# RCSS_CTRL register map
Vendor: Texas Instruments
Peripheral module from a debugger description file (folder am273).
Registers are 32-bit, read-write, no defined reset value unless marked. A register's access mark holds for its fields unless they carry their own. Offsets are as the file gives them; lines under a group give offsets from that group; [hi:lo] are bit positions; {n}, {i} and the like mark numbered series; 'fields as' and 'values as' point back to an identical list; <NAME> marks a mode.

## RCSS_CTRL
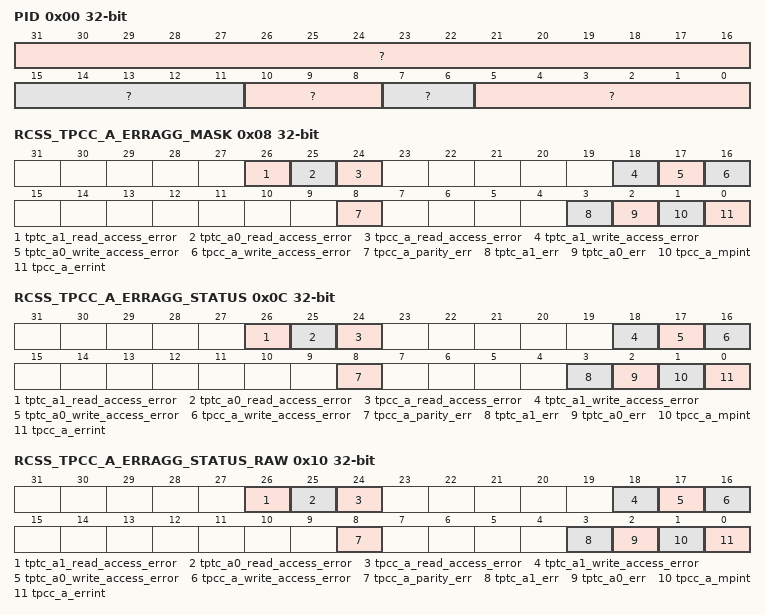
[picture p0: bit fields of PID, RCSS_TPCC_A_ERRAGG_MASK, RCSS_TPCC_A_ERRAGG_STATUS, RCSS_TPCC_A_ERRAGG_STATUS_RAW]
0x00 PID ro
  [31:16] ?, [15:11] ?, [10:8] ?, [7:6] ?, [5:0] ?
0x08 RCSS_TPCC_A_ERRAGG_MASK
  [26] tptc_a1_read_access_error — Mask Error from RCSS_TPTC_A1 to aggregated Error RCSS_TPCC_A_ERRAGG 1 : Error is Masked 0 : Error is Unmasked
  [25] tptc_a0_read_access_error — Mask Error from RCSS_TPTC_A0 to aggregated Error RCSS_TPCC_A_ERRAGG 1 : Error is Masked 0 : Error is Unmasked
  [24] tpcc_a_read_access_error — Mask Error from RCSS_TPCC_A to aggregated Error RCSS_TPCC_A_ERRAGG 1 : Error is Masked 0 : Error is Unmasked
  [18] tptc_a1_write_access_error — Mask Error from RCSS_TPTC_A1 to aggregated Error RCSS_TPCC_A_ERRAGG 1 : Error is Masked 0 : Error is Unmasked
  [17] tptc_a0_write_access_error — Mask Error from RCSS_TPTC_A0 to aggregated Error RCSS_TPCC_A_ERRAGG 1 : Error is Masked 0 : Error is Unmasked
  [16] tpcc_a_write_access_error — Mask Error from RCSS_TPCC_A to aggregated Error RCSS_TPCC_A_ERRAGG 1 : Error is Masked 0 : Error is Unmasked
  [8] tpcc_a_parity_err — Mask Error from RCSS_TPCC_A to aggregated Error RCSS_TPCC_A_ERRAGG 1 : Error is Masked 0 : Error is Unmasked
  [3] tptc_a1_err — Mask Error from RCSS_TPTC_A1 to aggregated Error RCSS_TPCC_A_ERRAGG 1 : Error is Masked 0 : Error is Unmasked
  [2] tptc_a0_err — Mask Error from RCSS_TPTC_A0 to aggregated Error RCSS_TPCC_A_ERRAGG 1 : Error is Masked 0 : Error is Unmasked
  [1] tpcc_a_mpint — Mask Error from RCSS_TPCC_A to aggregated Error RCSS_TPCC_A_ERRAGG 1 : Error is Masked 0 : Error is Unmasked
  [0] tpcc_a_errint — Mask Error from RCSS_TPCC_A to aggregated Error RCSS_TPCC_A_ERRAGG 1 : Error is Masked 0 : Error is Unmasked
0x0C RCSS_TPCC_A_ERRAGG_STATUS
  [26] tptc_a1_read_access_error — Status of Error from RCSS_TPTC_A1. Set only if Interupt is unmasked in RCSS_TPCC_A_ERRAGG_MASK Wrie 0x1 to clear this Error.
  [25] tptc_a0_read_access_error — Status of Error from RCSS_TPTC_A0. Set only if Interupt is unmasked in RCSS_TPCC_A_ERRAGG_MASK Wrie 0x1 to clear this Error.
  [24] tpcc_a_read_access_error — Status of Error from RCSS_TPCC_A. Set only if Interupt is unmasked in RCSS_TPCC_A_ERRAGG_MASK Wrie 0x1 to clear this Error.
  [18] tptc_a1_write_access_error — Status of Error from RCSS_TPTC_A1. Set only if Interupt is unmasked in RCSS_TPCC_A_ERRAGG_MASK Wrie 0x1 to clear this Error.
  [17] tptc_a0_write_access_error — Status of Error from RCSS_TPTC_A0. Set only if Interupt is unmasked in RCSS_TPCC_A_ERRAGG_MASK Wrie 0x1 to clear this Error.
  [16] tpcc_a_write_access_error — Status of Error from RCSS_TPCC_A. Set only if Interupt is unmasked in RCSS_TPCC_A_ERRAGG_MASK Wrie 0x1 to clear this Error.
  [8] tpcc_a_parity_err — Status of Error from RCSS_TPCC_A. Set only if Interupt is unmasked in RCSS_TPCC_A_ERRAGG_MASK Wrie 0x1 to clear this Error.
  [3] tptc_a1_err — Status of Error from RCSS_TPTC_A1. Set only if Interupt is unmasked in RCSS_TPCC_A_ERRAGG_MASK Wrie 0x1 to clear this Error.
  [2] tptc_a0_err — Status of Error from RCSS_TPTC_A0. Set only if Interupt is unmasked in RCSS_TPCC_A_ERRAGG_MASK Wrie 0x1 to clear this Error.
  [1] tpcc_a_mpint — Status of Error from RCSS_TPCC_A. Set only if Interupt is unmasked in RCSS_TPCC_A_ERRAGG_MASK Wrie 0x1 to clear this Error.
  [0] tpcc_a_errint — Status of Error from RCSS_TPCC_A. Set only if Interupt is unmasked in RCSS_TPCC_A_ERRAGG_MASK Wrie 0x1 to clear this Error.
0x10 RCSS_TPCC_A_ERRAGG_STATUS_RAW
  [26] tptc_a1_read_access_error — Raw Status of Error from RCSS_TPTC_A1. Set irrespective if the Interupt is masked or unmasked in RCSS_TPCC_A_ERRAGG_MASK
  [25] tptc_a0_read_access_error — Raw Status of Error from RCSS_TPTC_A0. Set irrespective if the Interupt is masked or unmasked in RCSS_TPCC_A_ERRAGG_MASK
  [24] tpcc_a_read_access_error — Raw Status of Error from RCSS_TPCC_A. Set irrespective if the Interupt is masked or unmasked in RCSS_TPCC_A_ERRAGG_MASK
  [18] tptc_a1_write_access_error — Raw Status of Error from RCSS_TPTC_A1. Set irrespective if the Interupt is masked or unmasked in RCSS_TPCC_A_ERRAGG_MASK
  [17] tptc_a0_write_access_error — Raw Status of Error from RCSS_TPTC_A0. Set irrespective if the Interupt is masked or unmasked in RCSS_TPCC_A_ERRAGG_MASK
  [16] tpcc_a_write_access_error — Raw Status of Error from RCSS_TPCC_A. Set irrespective if the Interupt is masked or unmasked in RCSS_TPCC_A_ERRAGG_MASK
  [8] tpcc_a_parity_err — Raw Status of Error from RCSS_TPCC_A. Set irrespective if the Interupt is masked or unmasked in RCSS_TPCC_A_ERRAGG_MASK
  [3] tptc_a1_err — Raw Status of Error from RCSS_TPTC_A1. Set irrespective if the Interupt is masked or unmasked in RCSS_TPCC_A_ERRAGG_MASK
  [2] tptc_a0_err — Raw Status of Error from RCSS_TPTC_A0. Set irrespective if the Interupt is masked or unmasked in RCSS_TPCC_A_ERRAGG_MASK
  [1] tpcc_a_mpint — Raw Status of Error from RCSS_TPCC_A. Set irrespective if the Interupt is masked or unmasked in RCSS_TPCC_A_ERRAGG_MASK
  [0] tpcc_a_errint — Raw Status of Error from RCSS_TPCC_A. Set irrespective if the Interupt is masked or unmasked in RCSS_TPCC_A_ERRAGG_MASK
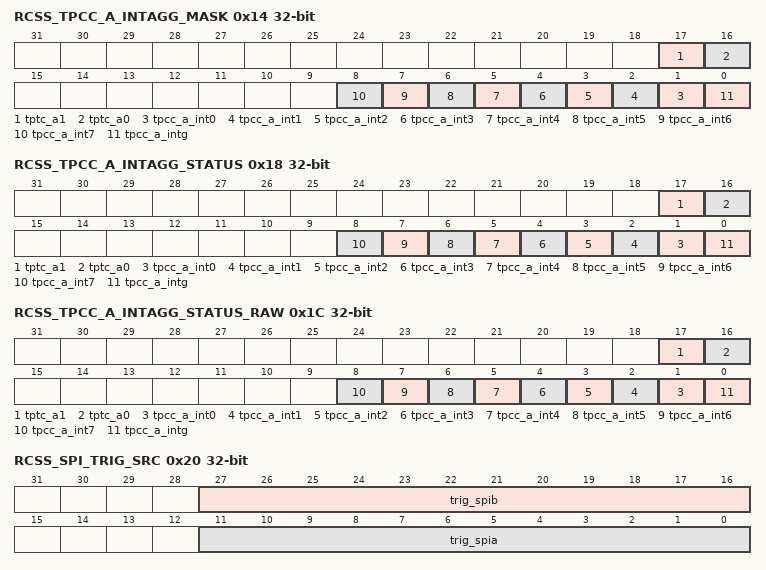
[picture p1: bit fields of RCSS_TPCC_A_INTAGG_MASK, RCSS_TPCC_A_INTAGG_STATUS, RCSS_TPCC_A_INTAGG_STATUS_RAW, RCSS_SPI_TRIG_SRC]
0x14 RCSS_TPCC_A_INTAGG_MASK
  [17] tptc_a1 — Mask Interrupt from TPTC A1 to aggregated Interrupt RCSS_TPCC_A_INTAGG 1 : Interrupt is Masked 0 : Interrupt is Unmasked
  [16] tptc_a0 — Mask Interrupt from TPTC A0 to aggregated Interrupt RCSS_TPCC_A_INTAGG 1 : Interrupt is Masked 0 : Interrupt is Unmasked
  [n+1] tpcc_a_int{n} (n=0..7) — Mask Interrupt from RCSS_TPCC_A to aggregated Interrupt RCSS_TPCC_A_INTAGG 1 : Interrupt is Masked 0 : Interrupt is Unmasked
  [0] tpcc_a_intg — Mask Interrupt from RCSS_TPCC_A to aggregated Interrupt RCSS_TPCC_A_INTAGG 1 : Interrupt is Masked 0 : Interrupt is Unmasked
0x18 RCSS_TPCC_A_INTAGG_STATUS
  [17] tptc_a1 — Status of Interrupt from TPTC A1. Set only if Interupt is unmasked in RCSS_TPCC_A_INTAGG_MASK Wrie 0x1 to clear this interrupt.
  [16] tptc_a0 — Status of Interrupt from TPTC A0. Set only if Interupt is unmasked in RCSS_TPCC_A_INTAGG_MASK Wrie 0x1 to clear this interrupt.
  [n+1] tpcc_a_int{n} (n=0..7) — Status of Interrupt from RCSS_TPCC_A. Set only if Interupt is unmasked in RCSS_TPCC_A_INTAGG_MASK Wrie 0x1 to clear this interrupt.
  [0] tpcc_a_intg — Status of Interrupt from RCSS_TPCC_A. Set only if Interupt is unmasked in RCSS_TPCC_A_INTAGG_MASK Wrie 0x1 to clear this interrupt.
0x1C RCSS_TPCC_A_INTAGG_STATUS_RAW
  [17] tptc_a1 — Raw Status of Interrupt from TPTC A1. Set irrespective if the Interupt is masked or unmasked in RCSS_TPCC_A_INTAGG_MASK
  [16] tptc_a0 — Raw Status of Interrupt from TPTC A0. Set irrespective if the Interupt is masked or unmasked in RCSS_TPCC_A_INTAGG_MASK
  [n+1] tpcc_a_int{n} (n=0..7) — Raw Status of Interrupt from RCSS_TPCC_A. Set irrespective if the Interupt is masked or unmasked in RCSS_TPCC_A_INTAGG_MASK
  [0] tpcc_a_intg — Raw Status of Interrupt from RCSS_TPCC_A. Set irrespective if the Interupt is masked or unmasked in RCSS_TPCC_A_INTAGG_MASK
0x20 RCSS_SPI_TRIG_SRC
  [27:16] trig_spib — Trigger sources for RCSS SPIB
  [11:0] trig_spia — Trigger sources for RCSS SPIA
0x24 RCSS_SPIA_MEMINIT
  [0] mem0_init — Write pulse bit field: Start Memory intialization of memory. Write 0x1 to start memory initilization. Write 0x0 after ensuring Memory intilization is in progress or has completed.
0x28 RCSS_SPIA_MEMINIT_DONE
  [0] mem0_done — Status field. Read value 0x1 indicates previously triggered Memory intialization of memory is complte. Write 0x1 to clear status.
0x2C RCSS_SPIA_MEMINIT_STATUS ro
  [0] mem0_status — Status field. Read value 0x1 indicates previously triggered Memory intialization of memory is in progress.
0x30 RCSS_SPIB_MEMINIT
  fields as RCSS_SPIA_MEMINIT
0x34 RCSS_SPIB_MEMINIT_DONE
  fields as RCSS_SPIA_MEMINIT_DONE
0x38 RCSS_SPIB_MEMINIT_STATUS ro
  fields as RCSS_SPIA_MEMINIT_STATUS
0x3C RCSS_TPCC_MEMINIT_START
  [0] tpcc_a_meminit_start — Write pulse bit field: Start Memory intialization of memory. Write 0x1 to start memory initilization. Write 0x0 after ensuring Memory intilization is in progress or has completed.
0x40 RCSS_TPCC_MEMINIT_DONE
  [0] tpcc_a_meminit_done — Status field. Read value 0x1 indicates previously triggered Memory intialization of memory is complte. Write 0x1 to clear status.
0x44 RCSS_TPCC_MEMINIT_STATUS ro
  [0] tpcc_a_meminit_status — Status field. Read value 0x1 indicates previously triggered Memory intialization of memory is in progress.
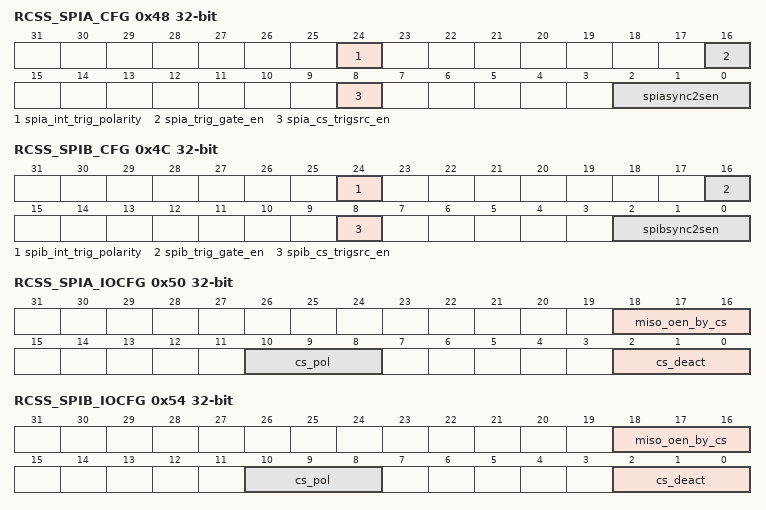
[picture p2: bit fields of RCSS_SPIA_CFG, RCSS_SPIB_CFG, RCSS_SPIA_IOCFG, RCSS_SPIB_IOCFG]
0x48 RCSS_SPIA_CFG
  [24] spia_int_trig_polarity — Trigger source polarity select. Write 0x0 : Polarity 0, Write 0x1 : Polarity 1
  [16] spia_trig_gate_en — Trigger Gate Enable. Write 0x1 : The triggers are un-gated only when chip-select is active
  [8] spia_cs_trigsrc_en — Chip Select Trigger SRC enable, Wrie 0x1 to Use CS as trigger source
  [2:0] spiasync2sen — Donot touch the field. Used as Tie-off for IP-config
0x4C RCSS_SPIB_CFG
  [24] spib_int_trig_polarity — Trigger source polarity select. Write 0x0 : Polarity 0, Write 0x1 : Polarity 1
  [16] spib_trig_gate_en — Trigger Gate Enable. Write 0x1 : The triggers are un-gated only when chip-select is active
  [8] spib_cs_trigsrc_en — Chip Select Trigger SRC enable, Wrie 0x1 to Use CS as trigger source
  [2:0] spibsync2sen — Donot touch the field. Used as Tie-off for IP-config
0x50 RCSS_SPIA_IOCFG
  [18:16] miso_oen_by_cs — SPI MISO Output Enable Control based on Chip select CS. Applicable in slave mode. Write 0x1 : MISO OEN controlled based on CS.When CS is inactive OE_N=1. Write 0x0 : MISO OEN controlled by IP
  [10:8] cs_pol — SPI CS polarity-slave mode. Write 0x1 : Active high. Write 0x0 : Active low
  [2:0] cs_deact — Chip Select Deactivate. Write 0x1 : SPI External chip select is overridden with the value of SPI CS polarity-slave mode
0x54 RCSS_SPIB_IOCFG
  fields as RCSS_SPIA_IOCFG
0x58 RCSS_SPI_HOST_IRQ
  [2:0] host_irq — TI internal reserved for R&D
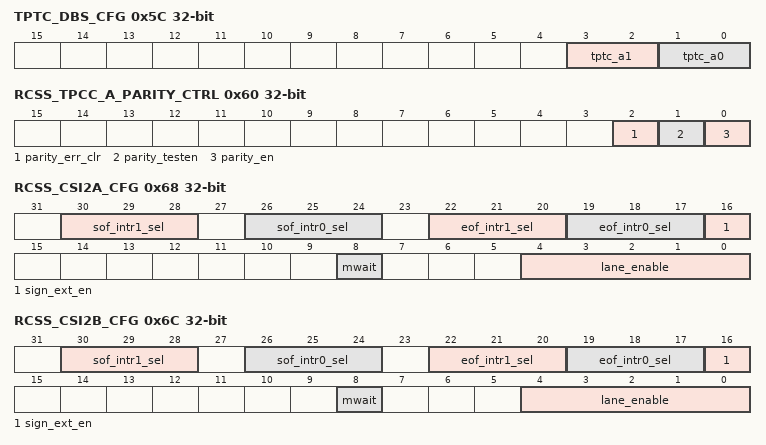
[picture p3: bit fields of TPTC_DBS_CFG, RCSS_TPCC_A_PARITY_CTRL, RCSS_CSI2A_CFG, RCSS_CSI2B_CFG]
0x5C TPTC_DBS_CFG
  [3:2] tptc_a1 — Max Burst size tieoff value for TPTC A1
  [1:0] tptc_a0 — Max Burst size tieoff value for TPTC A0
0x60 RCSS_TPCC_A_PARITY_CTRL
  [2] parity_err_clr — Write pulse bit field: Write 0x1 to clear the Parit Error status for TPCC
  [1] parity_testen — Enable Parity Test for TPCC. Write 0x1 : Parity Test is enabled on PARAM memory
  [0] parity_en — Enable Parity for TPCC. Write 0x1 : Parity is enabled on PARAM memory
0x64 RCSS_TPCC_A_PARITY_STATUS ro
  [15:8] parity_addr — TPCC Error Address at which Parity Error occurred
0x68 RCSS_CSI2A_CFG
  [30:28] sof_intr1_sel — Select the Start of Frame Contx to be sent as RCSS_CSI2A_SOF_INT1 Write 0 : Start of Frame for Context 0 will be propagated on this interrupt line Write 7 : Start of Frame for Context 7 will be propagated on this interrupt line
  [26:24] sof_intr0_sel — Select the Start of Frame Contx to be sent as RCSS_CSI2A_SOF_INT0 Write 0 : Start of Frame for Context 0 will be propagated on this interrupt line Write 7 : Start of Frame for Context 7 will be propagated on this interrupt line
  [22:20] eof_intr1_sel — Select the End of Frame Contx to be sent as RCSS_CSI2A_EOF_INT1 Write 0 : End of Frame for Context 0 will be propagated on this interrupt line Write 7 : End of Frame for Context 7 will be propagated on this interrupt line
  [19:17] eof_intr0_sel — Select the End of Frame Contx to be sent as RCSS_CSI2A_EOF_INT0 Write 0 : End of Frame for Context 0 will be propagated on this interrupt line Write 7 : End of Frame for Context 7 will be propagated on this interrupt line
  [16] sign_ext_en — Sign Extention Enable for CSI2 A
  [8] mwait — Power Idle Protocol related Mwait Port
  [4:0] lane_enable — Lane enable for CSI2 A
0x6C RCSS_CSI2B_CFG
  [30:28] sof_intr1_sel — Select the Start of Frame Contx to be sent as RCSS_CSI2B_SOF_INT1 Write 0 : Start of Frame for Context 0 will be propagated on this interrupt line Write 7 : Start of Frame for Context 7 will be propagated on this interrupt line
  [26:24] sof_intr0_sel — Select the Start of Frame Contx to be sent as RCSS_CSI2B_SOF_INT0 Write 0 : Start of Frame for Context 0 will be propagated on this interrupt line Write 7 : Start of Frame for Context 7 will be propagated on this interrupt line
  [22:20] eof_intr1_sel — Select the End of Frame Contx to be sent as RCSS_CSI2B_EOF_INT1 Write 0 : End of Frame for Context 0 will be propagated on this interrupt line Write 7 : End of Frame for Context 7 will be propagated on this interrupt line
  [19:17] eof_intr0_sel — Select the End of Frame Contx to be sent as RCSS_CSI2B_EOF_INT0 Write 0 : End of Frame for Context 0 will be propagated on this interrupt line Write 7 : End of Frame for Context 7 will be propagated on this interrupt line
  [16] sign_ext_en — Sign Extention Enable for CSI2 B
  [8] mwait — Power Idle Protocol related Mwait Port
  [4:0] lane_enable — Lane enable for CSI2 B
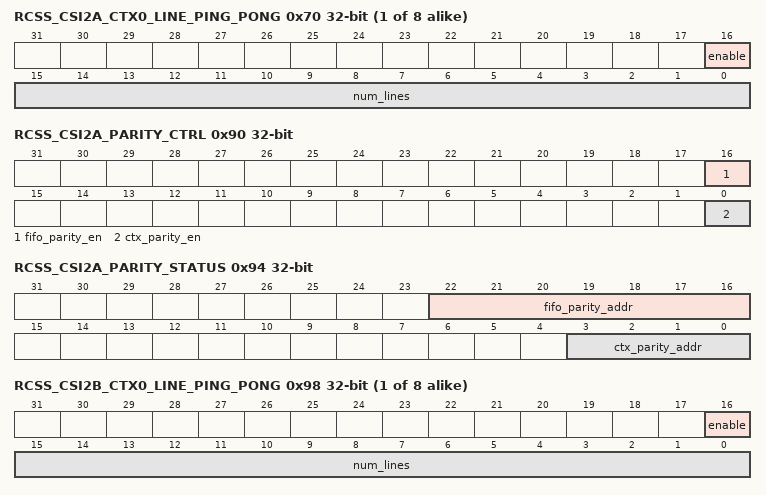
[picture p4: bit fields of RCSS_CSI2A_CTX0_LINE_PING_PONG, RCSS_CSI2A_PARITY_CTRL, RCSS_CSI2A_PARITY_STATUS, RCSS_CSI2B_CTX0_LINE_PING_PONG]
{0x70+4i} RCSS_CSI2A_CTX{i}_LINE_PING_PONG (i=0..7)
  [16] enable — Enable line based ping pong toggle for Context {i} 0 : Diabled 1:Enabled
  [15:0] num_lines — Configure the number of lines for ping pong toggle for Context {i}
0x90 RCSS_CSI2A_PARITY_CTRL
  [16] fifo_parity_en — Enable Parity for CSI2 FIFO Memory. Write 0x1 : Parity is enabled
  [0] ctx_parity_en — Enable Parity for CSI2 CTX Memory. Write 0x1 : Parity is enabled
0x94 RCSS_CSI2A_PARITY_STATUS ro
  [22:16] fifo_parity_addr — CSI2 FIFO Memory Error Address at which Parity Error occurred
  [3:0] ctx_parity_addr — CSI2 CTX Memory Error Address at which Parity Error occurred
{0x98+4i} RCSS_CSI2B_CTX{i}_LINE_PING_PONG (i=0..7)
  fields as RCSS_CSI2A_CTX0_LINE_PING_PONG
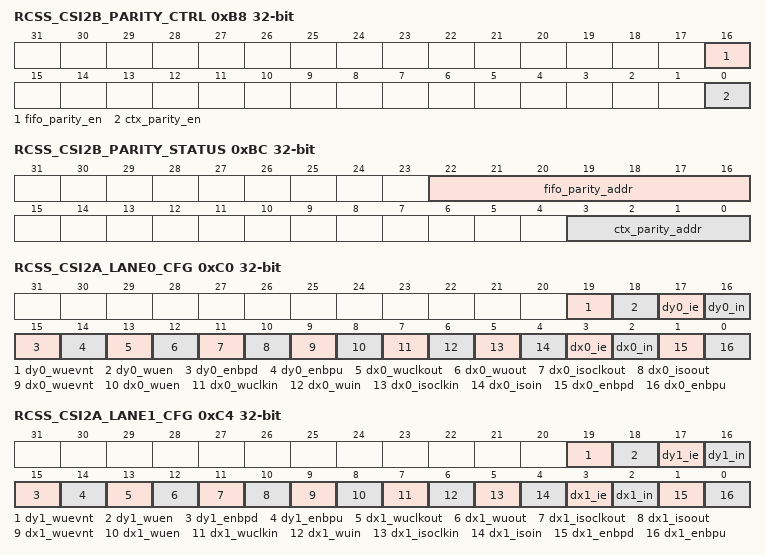
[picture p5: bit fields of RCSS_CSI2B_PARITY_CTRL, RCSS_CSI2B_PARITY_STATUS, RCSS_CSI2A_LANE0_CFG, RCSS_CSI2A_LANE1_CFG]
0xB8 RCSS_CSI2B_PARITY_CTRL
  fields as RCSS_CSI2A_PARITY_CTRL
0xBC RCSS_CSI2B_PARITY_STATUS ro
  fields as RCSS_CSI2A_PARITY_STATUS
0xC0 RCSS_CSI2A_LANE0_CFG access per field
  [19] dy0_wuevnt ro — Pad DY Wakeup Event
  [18] dy0_wuen rw — Pad DY Wakeup Enable
  [17] dy0_ie rw — Pad DY Input Buffer Enable
  [16] dy0_in ro — Pad DY Input
  [15] dy0_enbpd rw — Pad DY Enable Pull Down
  [14] dy0_enbpu rw — Pad DY Enable Pull Up
  [13] dx0_wuclkout ro — Pad DX Wakeup Clkout
  [12] dx0_wuout ro — Pad DX Wakeup Output
  [11] dx0_isoclkout ro — Pad DX Isosaltion Clkout
  [10] dx0_isoout ro — Pad DX Isosaltion Output
  [9] dx0_wuevnt ro — Pad DX Wakeup Event
  [8] dx0_wuen rw — Pad DX Wakeup Enable
  [7] dx0_wuclkin rw — Pad DX Wakeup Clkin
  [6] dx0_wuin rw — Pad DX Wakeup Input
  [5] dx0_isoclkin rw — Pad DX Isolation Clkin
  [4] dx0_isoin rw — Pad DX Isosaltion Input
  [3] dx0_ie rw — Pad DX Input Buffer Enable
  [2] dx0_in ro — Pad DX Input
  [1] dx0_enbpd rw — Pad DX Enable Pull Down
  [0] dx0_enbpu rw — Pad DX Enable Pull Up
0xC4 RCSS_CSI2A_LANE1_CFG access per field
  [19] dy1_wuevnt ro — Pad DY Wakeup Event
  [18] dy1_wuen rw — Pad DY Wakeup Enable
  [17] dy1_ie rw — Pad DY Input Buffer Enable
  [16] dy1_in ro — Pad DY Input
  [15] dy1_enbpd rw — Pad DY Enable Pull Down
  [14] dy1_enbpu rw — Pad DY Enable Pull Up
  [13] dx1_wuclkout ro — Pad DX Wakeup Clkout
  [12] dx1_wuout ro — Pad DX Wakeup Output
  [11] dx1_isoclkout ro — Pad DX Isosaltion Clkout
  [10] dx1_isoout ro — Pad DX Isosaltion Output
  [9] dx1_wuevnt ro — Pad DX Wakeup Event
  [8] dx1_wuen rw — Pad DX Wakeup Enable
  [7] dx1_wuclkin rw — Pad DX Wakeup Clkin
  [6] dx1_wuin rw — Pad DX Wakeup Input
  [5] dx1_isoclkin rw — Pad DX Isolation Clkin
  [4] dx1_isoin rw — Pad DX Isosaltion Input
  [3] dx1_ie rw — Pad DX Input Buffer Enable
  [2] dx1_in ro — Pad DX Input
  [1] dx1_enbpd rw — Pad DX Enable Pull Down
  [0] dx1_enbpu rw — Pad DX Enable Pull Up
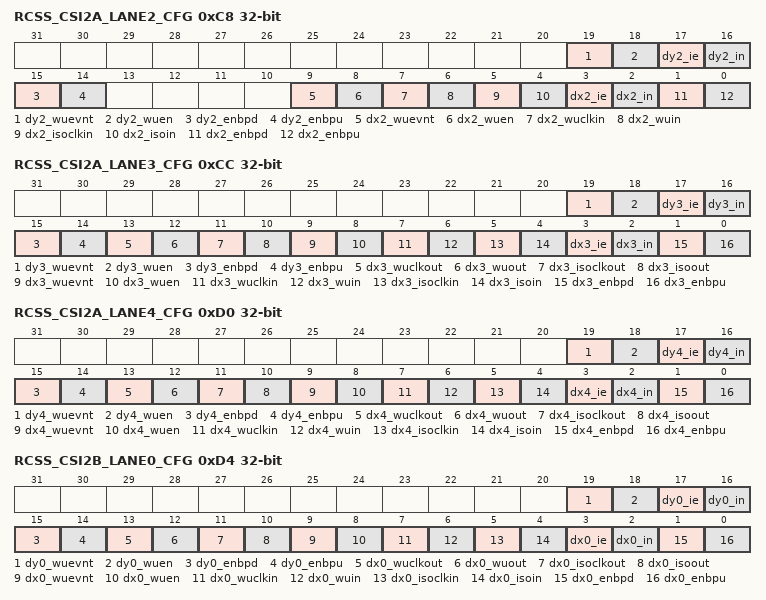
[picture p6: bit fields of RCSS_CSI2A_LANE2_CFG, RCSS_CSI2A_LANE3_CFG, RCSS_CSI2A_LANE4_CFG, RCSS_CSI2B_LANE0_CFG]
0xC8 RCSS_CSI2A_LANE2_CFG access per field
  [19] dy2_wuevnt ro — Pad DY Wakeup Event
  [18] dy2_wuen rw — Pad DY Wakeup Enable
  [17] dy2_ie rw — Pad DY Input Buffer Enable
  [16] dy2_in ro — Pad DY Input
  [15] dy2_enbpd rw — Pad DY Enable Pull Down
  [14] dy2_enbpu rw — Pad DY Enable Pull Up
  [9] dx2_wuevnt ro — Pad DX Wakeup Event
  [8] dx2_wuen rw — Pad DX Wakeup Enable
  [7] dx2_wuclkin rw — Pad DX Wakeup Clkin
  [6] dx2_wuin rw — Pad DX Wakeup Input
  [5] dx2_isoclkin rw — Pad DX Isolation Clkin
  [4] dx2_isoin rw — Pad DX Isosaltion Input
  [3] dx2_ie rw — Pad DX Input Buffer Enable
  [2] dx2_in ro — Pad DX Input
  [1] dx2_enbpd rw — Pad DX Enable Pull Down
  [0] dx2_enbpu rw — Pad DX Enable Pull Up
0xCC RCSS_CSI2A_LANE3_CFG access per field
  [19] dy3_wuevnt ro — Pad DY Wakeup Event
  [18] dy3_wuen rw — Pad DY Wakeup Enable
  [17] dy3_ie rw — Pad DY Input Buffer Enable
  [16] dy3_in ro — Pad DY Input
  [15] dy3_enbpd rw — Pad DY Enable Pull Down
  [14] dy3_enbpu rw — Pad DY Enable Pull Up
  [13] dx3_wuclkout ro — Pad DX Wakeup Clkout
  [12] dx3_wuout ro — Pad DX Wakeup Output
  [11] dx3_isoclkout ro — Pad DX Isosaltion Clkout
  [10] dx3_isoout ro — Pad DX Isosaltion Output
  [9] dx3_wuevnt ro — Pad DX Wakeup Event
  [8] dx3_wuen rw — Pad DX Wakeup Enable
  [7] dx3_wuclkin rw — Pad DX Wakeup Clkin
  [6] dx3_wuin rw — Pad DX Wakeup Input
  [5] dx3_isoclkin rw — Pad DX Isolation Clkin
  [4] dx3_isoin rw — Pad DX Isosaltion Input
  [3] dx3_ie rw — Pad DX Input Buffer Enable
  [2] dx3_in ro — Pad DX Input
  [1] dx3_enbpd rw — Pad DX Enable Pull Down
  [0] dx3_enbpu rw — Pad DX Enable Pull Up
0xD0 RCSS_CSI2A_LANE4_CFG access per field
  [19] dy4_wuevnt ro — Pad DY Wakeup Event
  [18] dy4_wuen rw — Pad DY Wakeup Enable
  [17] dy4_ie rw — Pad DY Input Buffer Enable
  [16] dy4_in ro — Pad DY Input
  [15] dy4_enbpd rw — Pad DY Enable Pull Down
  [14] dy4_enbpu rw — Pad DY Enable Pull Up
  [13] dx4_wuclkout ro — Pad DX Wakeup Clkout
  [12] dx4_wuout ro — Pad DX Wakeup Output
  [11] dx4_isoclkout ro — Pad DX Isosaltion Clkout
  [10] dx4_isoout ro — Pad DX Isosaltion Output
  [9] dx4_wuevnt ro — Pad DX Wakeup Event
  [8] dx4_wuen rw — Pad DX Wakeup Enable
  [7] dx4_wuclkin rw — Pad DX Wakeup Clkin
  [6] dx4_wuin rw — Pad DX Wakeup Input
  [5] dx4_isoclkin rw — Pad DX Isolation Clkin
  [4] dx4_isoin rw — Pad DX Isosaltion Input
  [3] dx4_ie rw — Pad DX Input Buffer Enable
  [2] dx4_in ro — Pad DX Input
  [1] dx4_enbpd rw — Pad DX Enable Pull Down
  [0] dx4_enbpu rw — Pad DX Enable Pull Up
0xD4 RCSS_CSI2B_LANE0_CFG access per field
  fields as RCSS_CSI2A_LANE0_CFG
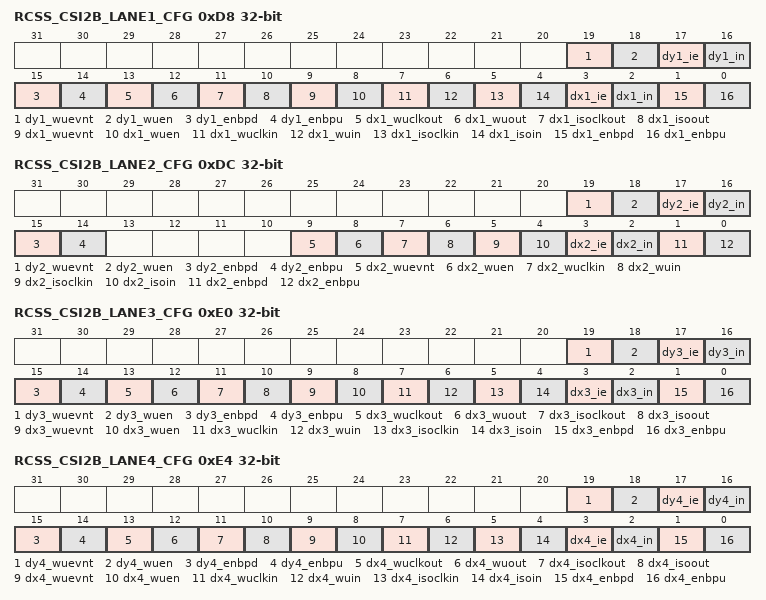
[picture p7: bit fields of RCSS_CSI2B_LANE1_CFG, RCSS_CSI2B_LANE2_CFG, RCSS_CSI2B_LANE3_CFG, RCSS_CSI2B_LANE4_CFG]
0xD8 RCSS_CSI2B_LANE1_CFG access per field
  fields as RCSS_CSI2A_LANE1_CFG
0xDC RCSS_CSI2B_LANE2_CFG access per field
  fields as RCSS_CSI2A_LANE2_CFG
0xE0 RCSS_CSI2B_LANE3_CFG access per field
  fields as RCSS_CSI2A_LANE3_CFG
0xE4 RCSS_CSI2B_LANE4_CFG access per field
  fields as RCSS_CSI2A_LANE4_CFG
0xE8 RCSS_CSI2A_FIFO_MEMINIT
  [0] start — Write pulse bit field: Start Memory intialization of memory. Write 0x1 to start memory initilization. Write 0x0 after ensuring Memory intilization is in progress or has completed.
0xEC RCSS_CSI2A_FIFO_MEMINIT_DONE
  [0] done — Status field. Read value 0x1 indicates previously triggered Memory intialization of memory is complte. Write 0x1 to clear status.
0xF0 RCSS_CSI2A_FIFO_MEMINIT_STATUS ro
  [0] status — Status field. Read value 0x1 indicates previously triggered Memory intialization of memory is in progress.
0xF4 RCSS_CSI2A_CTX_MEMINIT
  fields as RCSS_CSI2A_FIFO_MEMINIT
0xF8 RCSS_CSI2A_CTX_MEMINIT_DONE
  fields as RCSS_CSI2A_FIFO_MEMINIT_DONE
0xFC RCSS_CSI2A_CTX_MEMINIT_STATUS ro
  fields as RCSS_CSI2A_FIFO_MEMINIT_STATUS
0x100 RCSS_CSI2B_FIFO_MEMINIT
  fields as RCSS_CSI2A_FIFO_MEMINIT
0x104 RCSS_CSI2B_FIFO_MEMINIT_DONE
  fields as RCSS_CSI2A_FIFO_MEMINIT_DONE
0x108 RCSS_CSI2B_FIFO_MEMINIT_STATUS ro
  fields as RCSS_CSI2A_FIFO_MEMINIT_STATUS
0x10C RCSS_CSI2B_CTX_MEMINIT
  fields as RCSS_CSI2A_FIFO_MEMINIT
0x110 RCSS_CSI2B_CTX_MEMINIT_DONE
  fields as RCSS_CSI2A_FIFO_MEMINIT_DONE
0x114 RCSS_CSI2B_CTX_MEMINIT_STATUS ro
  fields as RCSS_CSI2A_FIFO_MEMINIT_STATUS
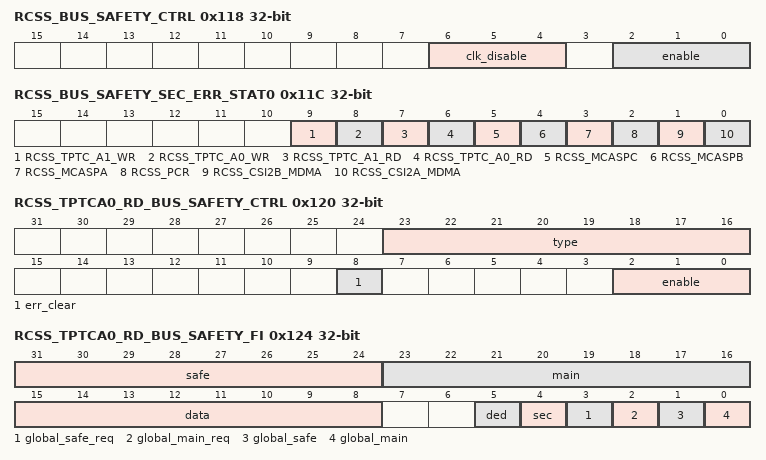
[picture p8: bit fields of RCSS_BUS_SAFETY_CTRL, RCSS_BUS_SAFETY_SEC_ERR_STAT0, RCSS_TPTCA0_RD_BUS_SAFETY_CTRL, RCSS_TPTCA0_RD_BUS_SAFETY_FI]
0x118 RCSS_BUS_SAFETY_CTRL
  [6:4] clk_disable — Option to clock gate the safety infrastructure is Safety is disabled
  [2:0] enable — Refer to TPR12 Substem Microarch document for more details
0x11C RCSS_BUS_SAFETY_SEC_ERR_STAT0 ro
  [9] RCSS_TPTC_A1_WR — Refer to TPR12 Substem Microarch document for more details
  [8] RCSS_TPTC_A0_WR — Refer to TPR12 Substem Microarch document for more details
  [7] RCSS_TPTC_A1_RD — Refer to TPR12 Substem Microarch document for more details
  [6] RCSS_TPTC_A0_RD — Refer to TPR12 Substem Microarch document for more details
  [5] RCSS_MCASPC — Refer to TPR12 Substem Microarch document for more details
  [4] RCSS_MCASPB — Refer to TPR12 Substem Microarch document for more details
  [3] RCSS_MCASPA — Refer to TPR12 Substem Microarch document for more details
  [2] RCSS_PCR — Refer to TPR12 Substem Microarch document for more details
  [1] RCSS_CSI2B_MDMA — Refer to TPR12 Substem Microarch document for more details
  [0] RCSS_CSI2A_MDMA — Refer to TPR12 Substem Microarch document for more details
0x120 RCSS_TPTCA0_RD_BUS_SAFETY_CTRL access per field
  [23:16] type ro — Refer to TPR12 Substem Microarch document for more details
  [8] err_clear rw — Refer to TPR12 Substem Microarch document for more details
  [2:0] enable rw — Refer to TPR12 Substem Microarch document for more details
0x124 RCSS_TPTCA0_RD_BUS_SAFETY_FI
  [31:24] safe — Refer to TPR12 Substem Microarch document for more details
  [23:16] main — Refer to TPR12 Substem Microarch document for more details
  [15:8] data — Refer to TPR12 Substem Microarch document for more details
  [5] ded — Refer to TPR12 Substem Microarch document for more details
  [4] sec — Refer to TPR12 Substem Microarch document for more details
  [3] global_safe_req — Refer to TPR12 Substem Microarch document for more details
  [2] global_main_req — Refer to TPR12 Substem Microarch document for more details
  [1] global_safe — Refer to TPR12 Substem Microarch document for more details
  [0] global_main — Refer to TPR12 Substem Microarch document for more details
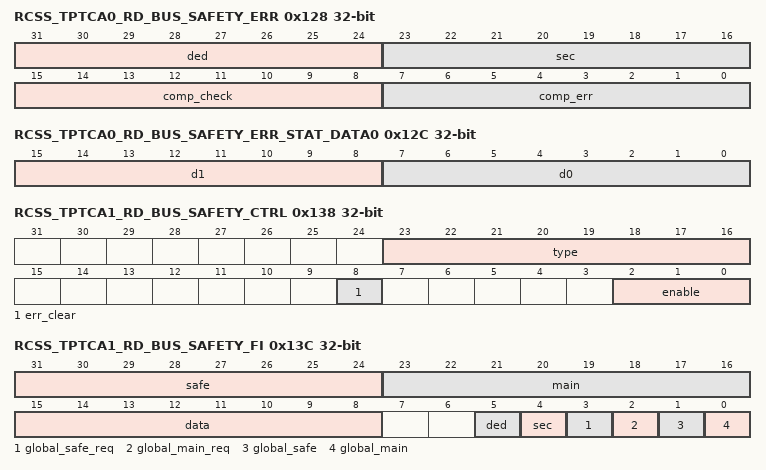
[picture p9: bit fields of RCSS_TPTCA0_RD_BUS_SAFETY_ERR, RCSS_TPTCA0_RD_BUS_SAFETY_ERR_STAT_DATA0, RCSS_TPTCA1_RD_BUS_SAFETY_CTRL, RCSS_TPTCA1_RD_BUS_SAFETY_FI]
0x128 RCSS_TPTCA0_RD_BUS_SAFETY_ERR ro
  [31:24] ded — Refer to TPR12 Substem Microarch document for more details
  [23:16] sec — Refer to TPR12 Substem Microarch document for more details
  [15:8] comp_check — Refer to TPR12 Substem Microarch document for more details
  [7:0] comp_err — Refer to TPR12 Substem Microarch document for more details
0x12C RCSS_TPTCA0_RD_BUS_SAFETY_ERR_STAT_DATA0 ro
  [15:8] d1 — Refer to TPR12 Substem Microarch document for more details
  [7:0] d0 — Refer to TPR12 Substem Microarch document for more details
0x130 RCSS_TPTCA0_RD_BUS_SAFETY_ERR_STAT_CMD ro
  [31:0] stat — Refer to TPR12 Substem Microarch document for more details
0x134 RCSS_TPTCA0_RD_BUS_SAFETY_ERR_STAT_READ ro
  fields as RCSS_TPTCA0_RD_BUS_SAFETY_ERR_STAT_CMD
0x138 RCSS_TPTCA1_RD_BUS_SAFETY_CTRL access per field
  fields as RCSS_TPTCA0_RD_BUS_SAFETY_CTRL
0x13C RCSS_TPTCA1_RD_BUS_SAFETY_FI
  fields as RCSS_TPTCA0_RD_BUS_SAFETY_FI
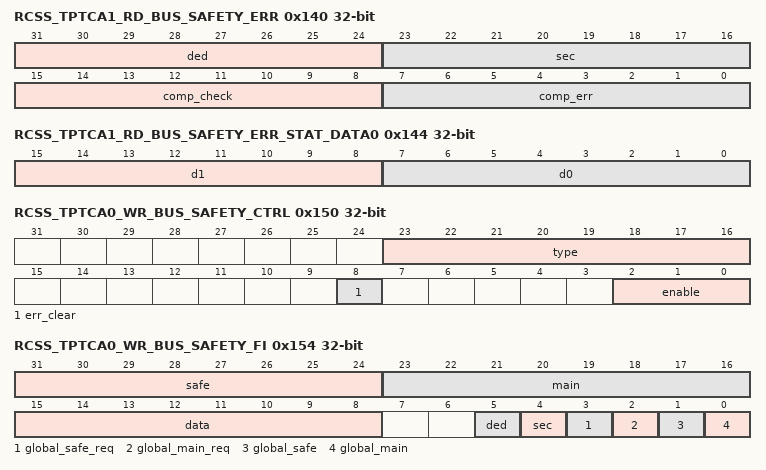
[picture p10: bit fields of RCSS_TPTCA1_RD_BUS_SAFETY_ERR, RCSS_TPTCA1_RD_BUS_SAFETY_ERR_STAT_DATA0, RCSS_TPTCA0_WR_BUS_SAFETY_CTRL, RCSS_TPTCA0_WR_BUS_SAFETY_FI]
0x140 RCSS_TPTCA1_RD_BUS_SAFETY_ERR ro
  fields as RCSS_TPTCA0_RD_BUS_SAFETY_ERR
0x144 RCSS_TPTCA1_RD_BUS_SAFETY_ERR_STAT_DATA0 ro
  fields as RCSS_TPTCA0_RD_BUS_SAFETY_ERR_STAT_DATA0
0x148 RCSS_TPTCA1_RD_BUS_SAFETY_ERR_STAT_CMD ro
  fields as RCSS_TPTCA0_RD_BUS_SAFETY_ERR_STAT_CMD
0x14C RCSS_TPTCA1_RD_BUS_SAFETY_ERR_STAT_READ ro
  fields as RCSS_TPTCA0_RD_BUS_SAFETY_ERR_STAT_CMD
0x150 RCSS_TPTCA0_WR_BUS_SAFETY_CTRL access per field
  fields as RCSS_TPTCA0_RD_BUS_SAFETY_CTRL
0x154 RCSS_TPTCA0_WR_BUS_SAFETY_FI
  fields as RCSS_TPTCA0_RD_BUS_SAFETY_FI
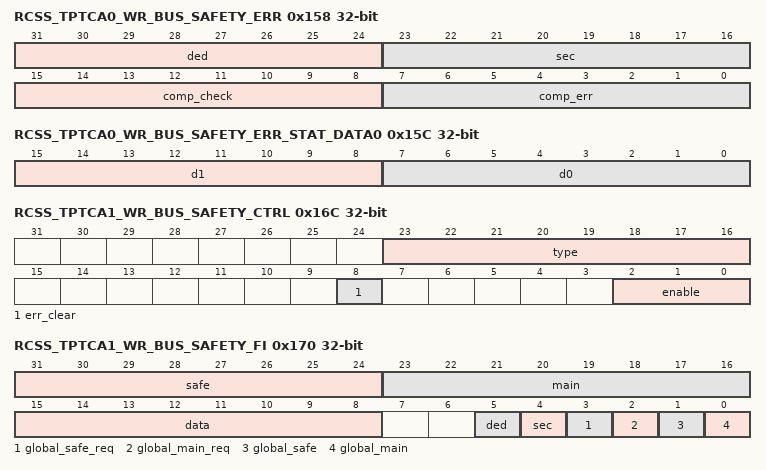
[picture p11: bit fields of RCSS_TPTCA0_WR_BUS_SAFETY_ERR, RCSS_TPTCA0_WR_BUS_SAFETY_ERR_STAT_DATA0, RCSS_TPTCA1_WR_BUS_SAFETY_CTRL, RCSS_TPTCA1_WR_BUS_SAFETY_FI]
0x158 RCSS_TPTCA0_WR_BUS_SAFETY_ERR ro
  fields as RCSS_TPTCA0_RD_BUS_SAFETY_ERR
0x15C RCSS_TPTCA0_WR_BUS_SAFETY_ERR_STAT_DATA0 ro
  fields as RCSS_TPTCA0_RD_BUS_SAFETY_ERR_STAT_DATA0
0x160 RCSS_TPTCA0_WR_BUS_SAFETY_ERR_STAT_CMD ro
  fields as RCSS_TPTCA0_RD_BUS_SAFETY_ERR_STAT_CMD
0x164 RCSS_TPTCA0_WR_BUS_SAFETY_ERR_STAT_WRITE ro
  fields as RCSS_TPTCA0_RD_BUS_SAFETY_ERR_STAT_CMD
0x168 RCSS_TPTCA0_WR_BUS_SAFETY_ERR_STAT_WRITERESP ro
  fields as RCSS_TPTCA0_RD_BUS_SAFETY_ERR_STAT_CMD
0x16C RCSS_TPTCA1_WR_BUS_SAFETY_CTRL access per field
  fields as RCSS_TPTCA0_RD_BUS_SAFETY_CTRL
0x170 RCSS_TPTCA1_WR_BUS_SAFETY_FI
  fields as RCSS_TPTCA0_RD_BUS_SAFETY_FI
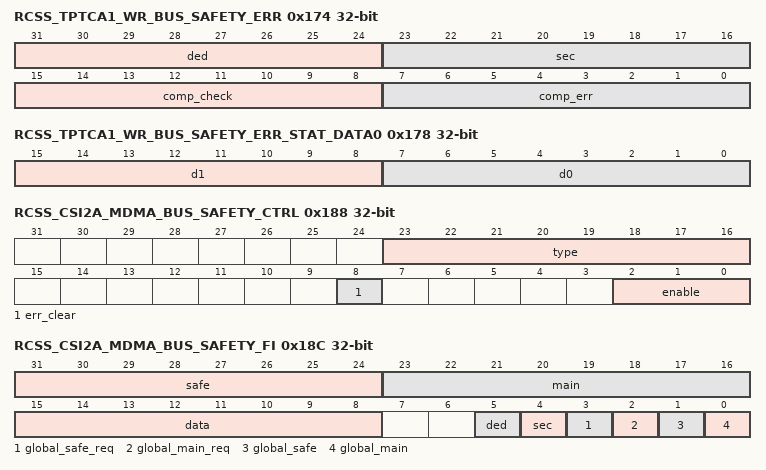
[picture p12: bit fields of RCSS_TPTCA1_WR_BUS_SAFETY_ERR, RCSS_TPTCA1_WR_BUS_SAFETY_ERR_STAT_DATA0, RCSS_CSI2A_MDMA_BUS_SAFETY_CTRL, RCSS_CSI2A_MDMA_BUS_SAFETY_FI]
0x174 RCSS_TPTCA1_WR_BUS_SAFETY_ERR ro
  fields as RCSS_TPTCA0_RD_BUS_SAFETY_ERR
0x178 RCSS_TPTCA1_WR_BUS_SAFETY_ERR_STAT_DATA0 ro
  fields as RCSS_TPTCA0_RD_BUS_SAFETY_ERR_STAT_DATA0
0x17C RCSS_TPTCA1_WR_BUS_SAFETY_ERR_STAT_CMD ro
  fields as RCSS_TPTCA0_RD_BUS_SAFETY_ERR_STAT_CMD
0x180 RCSS_TPTCA1_WR_BUS_SAFETY_ERR_STAT_WRITE ro
  fields as RCSS_TPTCA0_RD_BUS_SAFETY_ERR_STAT_CMD
0x184 RCSS_TPTCA1_WR_BUS_SAFETY_ERR_STAT_WRITERESP ro
  fields as RCSS_TPTCA0_RD_BUS_SAFETY_ERR_STAT_CMD
0x188 RCSS_CSI2A_MDMA_BUS_SAFETY_CTRL access per field
  fields as RCSS_TPTCA0_RD_BUS_SAFETY_CTRL
0x18C RCSS_CSI2A_MDMA_BUS_SAFETY_FI
  fields as RCSS_TPTCA0_RD_BUS_SAFETY_FI
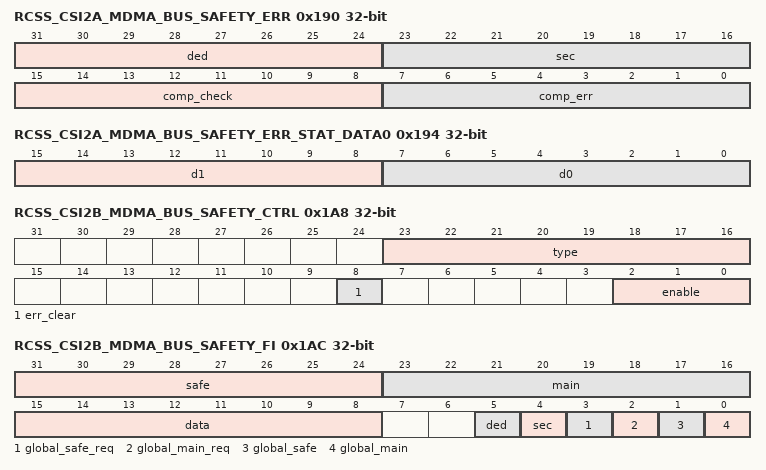
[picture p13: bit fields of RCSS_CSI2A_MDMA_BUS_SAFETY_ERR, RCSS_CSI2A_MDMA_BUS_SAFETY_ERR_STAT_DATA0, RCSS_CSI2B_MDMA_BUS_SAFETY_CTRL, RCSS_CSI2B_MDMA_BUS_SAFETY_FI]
0x190 RCSS_CSI2A_MDMA_BUS_SAFETY_ERR ro
  fields as RCSS_TPTCA0_RD_BUS_SAFETY_ERR
0x194 RCSS_CSI2A_MDMA_BUS_SAFETY_ERR_STAT_DATA0 ro
  fields as RCSS_TPTCA0_RD_BUS_SAFETY_ERR_STAT_DATA0
0x198 RCSS_CSI2A_MDMA_BUS_SAFETY_ERR_STAT_CMD ro
  fields as RCSS_TPTCA0_RD_BUS_SAFETY_ERR_STAT_CMD
0x19C RCSS_CSI2A_MDMA_BUS_SAFETY_ERR_STAT_WRITE ro
  fields as RCSS_TPTCA0_RD_BUS_SAFETY_ERR_STAT_CMD
0x1A0 RCSS_CSI2A_MDMA_BUS_SAFETY_ERR_STAT_READ ro
  fields as RCSS_TPTCA0_RD_BUS_SAFETY_ERR_STAT_CMD
0x1A4 RCSS_CSI2A_MDMA_BUS_SAFETY_ERR_STAT_WRITERESP ro
  fields as RCSS_TPTCA0_RD_BUS_SAFETY_ERR_STAT_CMD
0x1A8 RCSS_CSI2B_MDMA_BUS_SAFETY_CTRL access per field
  fields as RCSS_TPTCA0_RD_BUS_SAFETY_CTRL
0x1AC RCSS_CSI2B_MDMA_BUS_SAFETY_FI
  fields as RCSS_TPTCA0_RD_BUS_SAFETY_FI
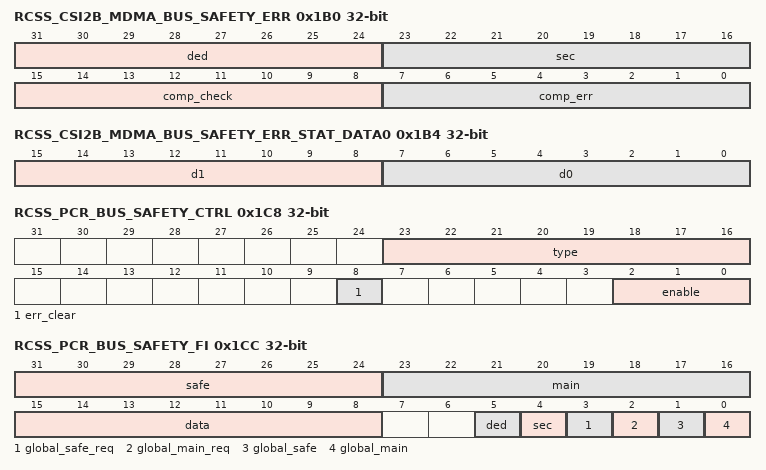
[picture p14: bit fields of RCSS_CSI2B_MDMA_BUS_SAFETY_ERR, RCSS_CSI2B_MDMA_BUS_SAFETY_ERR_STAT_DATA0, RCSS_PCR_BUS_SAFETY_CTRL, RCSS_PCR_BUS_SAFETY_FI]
0x1B0 RCSS_CSI2B_MDMA_BUS_SAFETY_ERR ro
  fields as RCSS_TPTCA0_RD_BUS_SAFETY_ERR
0x1B4 RCSS_CSI2B_MDMA_BUS_SAFETY_ERR_STAT_DATA0 ro
  fields as RCSS_TPTCA0_RD_BUS_SAFETY_ERR_STAT_DATA0
0x1B8 RCSS_CSI2B_MDMA_BUS_SAFETY_ERR_STAT_CMD ro
  fields as RCSS_TPTCA0_RD_BUS_SAFETY_ERR_STAT_CMD
0x1BC RCSS_CSI2B_MDMA_BUS_SAFETY_ERR_STAT_WRITE ro
  fields as RCSS_TPTCA0_RD_BUS_SAFETY_ERR_STAT_CMD
0x1C0 RCSS_CSI2B_MDMA_BUS_SAFETY_ERR_STAT_READ ro
  fields as RCSS_TPTCA0_RD_BUS_SAFETY_ERR_STAT_CMD
0x1C4 RCSS_CSI2B_MDMA_BUS_SAFETY_ERR_STAT_WRITERESP ro
  fields as RCSS_TPTCA0_RD_BUS_SAFETY_ERR_STAT_CMD
0x1C8 RCSS_PCR_BUS_SAFETY_CTRL access per field
  fields as RCSS_TPTCA0_RD_BUS_SAFETY_CTRL
0x1CC RCSS_PCR_BUS_SAFETY_FI
  fields as RCSS_TPTCA0_RD_BUS_SAFETY_FI
0x1D0 RCSS_PCR_BUS_SAFETY_ERR ro
  fields as RCSS_TPTCA0_RD_BUS_SAFETY_ERR
0x1D4 RCSS_PCR_BUS_SAFETY_ERR_STAT_DATA0 ro
  fields as RCSS_TPTCA0_RD_BUS_SAFETY_ERR_STAT_DATA0
0x1D8 RCSS_PCR_BUS_SAFETY_ERR_STAT_CMD ro
  fields as RCSS_TPTCA0_RD_BUS_SAFETY_ERR_STAT_CMD
0x1DC RCSS_PCR_BUS_SAFETY_ERR_STAT_WRITE ro
  fields as RCSS_TPTCA0_RD_BUS_SAFETY_ERR_STAT_CMD
0x1E0 RCSS_PCR_BUS_SAFETY_ERR_STAT_READ ro
  fields as RCSS_TPTCA0_RD_BUS_SAFETY_ERR_STAT_CMD
0x1E4 RCSS_PCR_BUS_SAFETY_ERR_STAT_WRITERESP ro
  fields as RCSS_TPTCA0_RD_BUS_SAFETY_ERR_STAT_CMD
0x1E8 RCSS_MCASPA_BUS_SAFETY_CTRL access per field
  fields as RCSS_TPTCA0_RD_BUS_SAFETY_CTRL
0x1EC RCSS_MCASPA_BUS_SAFETY_FI
  fields as RCSS_TPTCA0_RD_BUS_SAFETY_FI
0x1F0 RCSS_MCASPA_BUS_SAFETY_ERR ro
  fields as RCSS_TPTCA0_RD_BUS_SAFETY_ERR
0x1F4 RCSS_MCASPA_BUS_SAFETY_ERR_STAT_DATA0 ro
  fields as RCSS_TPTCA0_RD_BUS_SAFETY_ERR_STAT_DATA0
0x1F8 RCSS_MCASPA_BUS_SAFETY_ERR_STAT_CMD ro
  fields as RCSS_TPTCA0_RD_BUS_SAFETY_ERR_STAT_CMD
0x1FC RCSS_MCASPA_BUS_SAFETY_ERR_STAT_WRITE ro
  fields as RCSS_TPTCA0_RD_BUS_SAFETY_ERR_STAT_CMD
0x200 RCSS_MCASPA_BUS_SAFETY_ERR_STAT_READ ro
  fields as RCSS_TPTCA0_RD_BUS_SAFETY_ERR_STAT_CMD
0x204 RCSS_MCASPA_BUS_SAFETY_ERR_STAT_WRITERESP ro
  fields as RCSS_TPTCA0_RD_BUS_SAFETY_ERR_STAT_CMD
0x208 RCSS_MCASPB_BUS_SAFETY_CTRL access per field
  fields as RCSS_TPTCA0_RD_BUS_SAFETY_CTRL
0x20C RCSS_MCASPB_BUS_SAFETY_FI
  fields as RCSS_TPTCA0_RD_BUS_SAFETY_FI
0x210 RCSS_MCASPB_BUS_SAFETY_ERR ro
  fields as RCSS_TPTCA0_RD_BUS_SAFETY_ERR
0x214 RCSS_MCASPB_BUS_SAFETY_ERR_STAT_DATA0 ro
  fields as RCSS_TPTCA0_RD_BUS_SAFETY_ERR_STAT_DATA0
0x218 RCSS_MCASPB_BUS_SAFETY_ERR_STAT_CMD ro
  fields as RCSS_TPTCA0_RD_BUS_SAFETY_ERR_STAT_CMD
0x21C RCSS_MCASPB_BUS_SAFETY_ERR_STAT_WRITE ro
  fields as RCSS_TPTCA0_RD_BUS_SAFETY_ERR_STAT_CMD
0x220 RCSS_MCASPB_BUS_SAFETY_ERR_STAT_READ ro
  fields as RCSS_TPTCA0_RD_BUS_SAFETY_ERR_STAT_CMD
0x224 RCSS_MCASPB_BUS_SAFETY_ERR_STAT_WRITERESP ro
  fields as RCSS_TPTCA0_RD_BUS_SAFETY_ERR_STAT_CMD
0x228 RCSS_MCASPC_BUS_SAFETY_CTRL access per field
  fields as RCSS_TPTCA0_RD_BUS_SAFETY_CTRL
0x22C RCSS_MCASPC_BUS_SAFETY_FI
  fields as RCSS_TPTCA0_RD_BUS_SAFETY_FI
0x230 RCSS_MCASPC_BUS_SAFETY_ERR ro
  fields as RCSS_TPTCA0_RD_BUS_SAFETY_ERR
0x234 RCSS_MCASPC_BUS_SAFETY_ERR_STAT_DATA0 ro
  fields as RCSS_TPTCA0_RD_BUS_SAFETY_ERR_STAT_DATA0
0x238 RCSS_MCASPC_BUS_SAFETY_ERR_STAT_CMD ro
  fields as RCSS_TPTCA0_RD_BUS_SAFETY_ERR_STAT_CMD
0x23C RCSS_MCASPC_BUS_SAFETY_ERR_STAT_WRITE ro
  fields as RCSS_TPTCA0_RD_BUS_SAFETY_ERR_STAT_CMD
0x240 RCSS_MCASPC_BUS_SAFETY_ERR_STAT_READ ro
  fields as RCSS_TPTCA0_RD_BUS_SAFETY_ERR_STAT_CMD
0x244 RCSS_MCASPC_BUS_SAFETY_ERR_STAT_WRITERESP ro
  fields as RCSS_TPTCA0_RD_BUS_SAFETY_ERR_STAT_CMD
0x248 RCSS_SCIA_CTRL
  [4] DMA_RX_CLR — RCSS_SCIA RX DMA Clear. Write 0x1 to Clear the Receive DMA Request
  [0] DMA_TX_CLR — RCSS_SCIA TX DMA Clear. Write 0x1 to Clear the Transmit DMA Request
0x24C RCSS_GIO_CFG
  [31:0] gio_config — bit0 : writing '1' will slect negedge for pulse generation of GIO_PAD_INT0 to IRQ bit1 : writing '1' will slect negedge for pulse generation of GIO_PAD_INT1to IRQ bit2: writing '1' will slect negedge for pulse generation of GIO_PAD_INT2 to IRQ bit3 : writing '1' will slect negedge for pulse generation of GIO_PAD_INT3 to IRQ bit4 : writing '1' will slect negedge for pulse generation of GIO_PAD_INT4 to IRQ bit5 : writing '1' will slect negedge for pulse generation of GIO_PAD_INT5 to IRQ bit6 : writing '1' will slect negedge for pulse generation of GIO_PAD_INT6 to IRQ bit7 : writing '1' will slect negedge for pulse generation of GIO_PAD_INT7 to IRQ
0x250 RCSS_TPTC_BOUNDARY_CFG
  [13:8] tptc_a1_size — 6 bit signal used for deciding the boundary crossing size for CID-RID-SID reordering of TPTC Example: writing 6'd19 decidies boundary to be 2^19 i.e. 512 KB
  [5:0] tptc_a0_size — 6 bit signal used for deciding the boundary crossing size for CID-RID-SID reordering of TPTC Example: writing 6'd19 decidies boundary to be 2^19 i.e. 512 KB
0x254 RCSS_TPTC_XID_REORDER_CFG
  [8] tptc_a1_disable — Writing 1'b1 will disable the CID-RID-SID reodering feature for the TPTC instance
  [0] tptc_a0_disable — Writing 1'b1 will disable the CID-RID-SID reodering feature for the TPTC instance
0x258 DBG_ACK_CPU_CTRL
  [0] sel — Select the Processor Suspend that is used to Suspend the DSS Peripehrals 0: DSP 1:MSS CR5
0x25C DBG_ACK_CTL0
  [10:8] RCSS_ECAP — Enable Suspend of the peripheral. 0 : Peripheral not suspended 1: Peripehal Suspended
  [6:4] RCSS_I2CB — Enable Suspend of the peripheral. 0 : Peripheral not suspended 1: Peripehal Suspended
  [2:0] RCSS_I2CA — Enable Suspend of the peripheral. 0 : Peripheral not suspended 1: Peripehal Suspended
{0xFD0+4i} HW_SPARE_RW{i} (i=0..3)
  [31:0] hw_spare_rw{i} — Reserved for HW R&D
{0xFE0+4i} HW_SPARE_RO{i} ro (i=0..3)
  [31:0] hw_spare_ro{i} — Reserved for HW R&D
0xFF0 HW_SPARE_WPH
  [31:0] hw_spare_wph — Reserved for HW R&D
0xFF4 HW_SPARE_REC
  [n] hw_spare_rec{n} (n=0..31) — Reserved for HW R&D
0x1008 LOCK0_KICK0 — - KICK0 component
  [31:0] ?
0x100C LOCK0_KICK1 — - KICK1 component
  [31:0] ?
0x1010 intr_raw_status — Interrupt Raw Status/Set Register
  [3] ? — Proxy0 access violation error. Raw status is read. Write a 1 to set the status. Writing a 0 has no effect.
  [2] ? — Kick access violation error. Raw status is read. Write a 1 to set the status. Writing a 0 has no effect.
  [1] ? — Addressing violation error. Raw status is read. Write a 1 to set the status. Writing a 0 has no effect.
  [0] ? — Protection violation error. Raw status is read. Write a 1 to set the status. Writing a 0 has no effect.
0x1014 intr_enabled_status_clear — Interrupt Enabled Status/Clear register
  [3] ? — Proxy0 access violation error. Enabled status is read. Write a 1 to clear the status. Writing a 0 has no effect.
  [2] ? — Kick access violation error. Enabled status is read. Write a 1 to clear the status. Writing a 0 has no effect.
  [1] ? — Addressing violation error. Enabled status is read. Write a 1 to clear the status. Writing a 0 has no effect.
  [0] ? — Protection violation error. Enabled status is read. Write a 1 to clear the status. Writing a 0 has no effect.
0x1018 intr_enable — Interrupt Enable register
  [3] ? — Proxy0 access violation error enable. Write a 1 to set the enable. Writing a 0 has no effect.
  [2] ? — Kick access violation error enable. Write a 1 to set the enable. Writing a 0 has no effect.
  [1] ? — Addressing violation error enable. Write a 1 to set the enable. Writing a 0 has no effect.
  [0] ? — Protection violation error enable. Write a 1 to set the enable. Writing a 0 has no effect.
0x101C intr_enable_clear — Interrupt Enable Clear register
  [3] ? — Proxy0 access violation error enable clear. Write a 1 to clear the enable. Writing a 0 has no effect.
  [2] ? — Kick access violation error enable clear. Write a 1 to clear the enable. Writing a 0 has no effect.
  [1] ? — Addressing violation error enable clear. Write a 1 to clear the enable. Writing a 0 has no effect.
  [0] ? — Protection violation error enable clear. Write a 1 to clear the enable. Writing a 0 has no effect.
0x1020 eoi
  [7:0] ? — EOI vector value. Write this with interrupt distribution value in the chip.
0x1024 fault_address ro
  [31:0] ? — Fault Address.
0x1028 fault_type_status ro
  [6] ? — Non-secure access.
  [5:0] ? — Fault Type 10_0000 = Supervisor read fault - priv = 1 dir = 1 dtype != 1 01_0000 = Supervisor write fault - priv = 1 dir = 0 00_1000 = Supervisor execute fault - priv = 1 dir = 1 dtype = 1 00_0100 = User read fault - priv = 0 dir = 1 dtype = 1 00_0010 = User write fault - priv = 0 dir = 0 00_0001 = User execute fault - priv = 0 dir = 1 dtype = 1 00_0000 = No fault
0x102C fault_attr_status ro — Fault Attribute Status register
  [31:20] ? — XID.
  [19:8] ? — Route ID.
  [7:0] ? — Privilege ID.
0x1030 fault_clear wo
  [0] ? — Fault clear. Writing a 1 clears the current fault. Writing a 0 has no effect.
